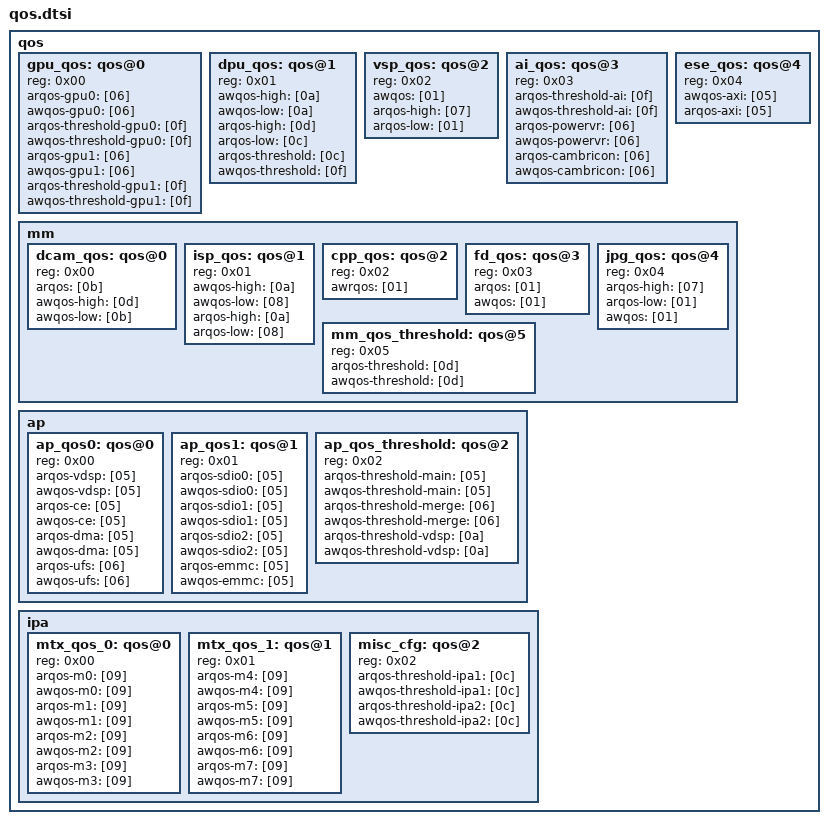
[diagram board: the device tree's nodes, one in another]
/*
 * iclass-c8pro hardware description; included in place from the board DTS.
 * Copyright (C) 2026 Evarentha - Linux 5.15 board port changes.
 */

	qos {
		#address-cells = <0x01>;
		#size-cells = <0x00>;
		ranges;

		gpu_qos: qos@0 {
			reg = <0x00>;
			arqos-gpu0 = [06];
			awqos-gpu0 = [06];
			arqos-threshold-gpu0 = [0f];
			awqos-threshold-gpu0 = [0f];
			arqos-gpu1 = [06];
			awqos-gpu1 = [06];
			arqos-threshold-gpu1 = [0f];
			awqos-threshold-gpu1 = [0f];
			phandle = <0x0b>;
		};

		dpu_qos: qos@1 {
			reg = <0x01>;
			awqos-high = [0a];
			awqos-low = [0a];
			arqos-high = [0d];
			arqos-low = [0c];
			arqos-threshold = [0c];
			awqos-threshold = [0f];
			phandle = <0x1f>;
		};

		vsp_qos: qos@2 {
			reg = <0x02>;
			awqos = [01];
			arqos-high = [07];
			arqos-low = [01];
			phandle = <0x34>;
		};

		ai_qos: qos@3 {
			reg = <0x03>;
			arqos-threshold-ai = [0f];
			awqos-threshold-ai = [0f];
			arqos-powervr = [06];
			awqos-powervr = [06];
			arqos-cambricon = [06];
			awqos-cambricon = [06];
			phandle = <0xb2>;
		};

		ese_qos: qos@4 {
			reg = <0x04>;
			awqos-axi = [05];
			arqos-axi = [05];
			phandle = <0x129>;
		};

		mm {

			dcam_qos: qos@0 {
				reg = <0x00>;
				arqos = [0b];
				awqos-high = [0d];
				awqos-low = [0b];
				phandle = <0x12a>;
			};

			isp_qos: qos@1 {
				reg = <0x01>;
				awqos-high = [0a];
				awqos-low = [08];
				arqos-high = [0a];
				arqos-low = [08];
				phandle = <0x12b>;
			};

			cpp_qos: qos@2 {
				reg = <0x02>;
				awrqos = [01];
				phandle = <0x12c>;
			};

			fd_qos: qos@3 {
				reg = <0x03>;
				arqos = [01];
				awqos = [01];
				phandle = <0x12d>;
			};

			jpg_qos: qos@4 {
				reg = <0x04>;
				arqos-high = [07];
				arqos-low = [01];
				awqos = [01];
				phandle = <0x12>;
			};

			mm_qos_threshold: qos@5 {
				reg = <0x05>;
				arqos-threshold = [0d];
				awqos-threshold = [0d];
				phandle = <0x12e>;
			};
		};

		ap {

			ap_qos0: qos@0 {
				reg = <0x00>;
				arqos-vdsp = [05];
				awqos-vdsp = [05];
				arqos-ce = [05];
				awqos-ce = [05];
				arqos-dma = [05];
				awqos-dma = [05];
				arqos-ufs = [06];
				awqos-ufs = [06];
				phandle = <0x12f>;
			};

			ap_qos1: qos@1 {
				reg = <0x01>;
				arqos-sdio0 = [05];
				awqos-sdio0 = [05];
				arqos-sdio1 = [05];
				awqos-sdio1 = [05];
				arqos-sdio2 = [05];
				awqos-sdio2 = [05];
				arqos-emmc = [05];
				awqos-emmc = [05];
				phandle = <0x130>;
			};

			ap_qos_threshold: qos@2 {
				reg = <0x02>;
				arqos-threshold-main = [05];
				awqos-threshold-main = [05];
				arqos-threshold-merge = [06];
				awqos-threshold-merge = [06];
				arqos-threshold-vdsp = [0a];
				awqos-threshold-vdsp = [0a];
				phandle = <0x131>;
			};
		};

		ipa {

			mtx_qos_0: qos@0 {
				reg = <0x00>;
				arqos-m0 = [09];
				awqos-m0 = [09];
				arqos-m1 = [09];
				awqos-m1 = [09];
				arqos-m2 = [09];
				awqos-m2 = [09];
				arqos-m3 = [09];
				awqos-m3 = [09];
				phandle = <0x132>;
			};

			mtx_qos_1: qos@1 {
				reg = <0x01>;
				arqos-m4 = [09];
				awqos-m4 = [09];
				arqos-m5 = [09];
				awqos-m5 = [09];
				arqos-m6 = [09];
				awqos-m6 = [09];
				arqos-m7 = [09];
				awqos-m7 = [09];
				phandle = <0x133>;
			};

			misc_cfg: qos@2 {
				reg = <0x02>;
				arqos-threshold-ipa1 = [0c];
				awqos-threshold-ipa1 = [0c];
				arqos-threshold-ipa2 = [0c];
				awqos-threshold-ipa2 = [0c];
				phandle = <0x134>;
			};
		};
	};

